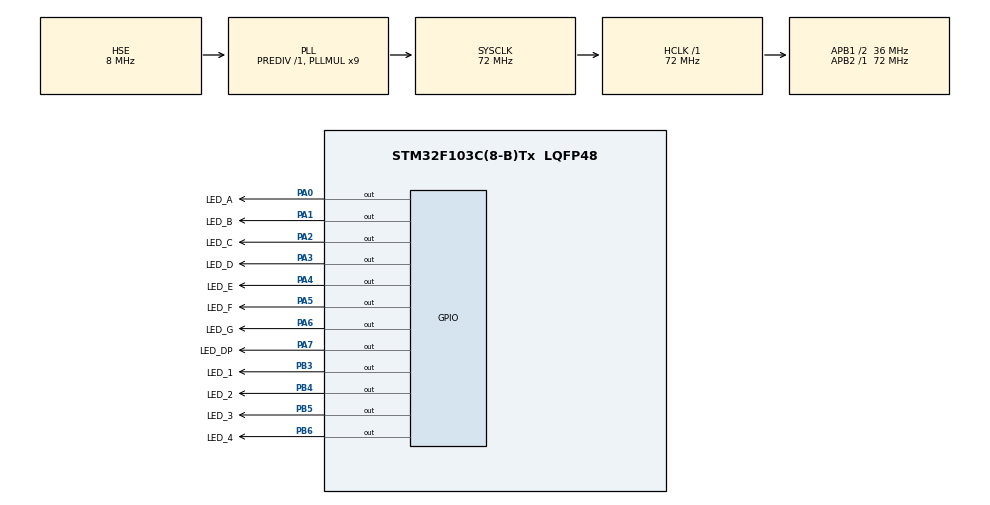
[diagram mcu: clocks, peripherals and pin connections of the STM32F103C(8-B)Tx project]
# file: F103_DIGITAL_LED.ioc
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Mcu.Family=STM32F1
RCC.PLLSourceVirtual=RCC_PLLSOURCE_HSE
PA2.GPIO_PuPd=GPIO_PULLDOWN
PD1-OSC_OUT.Mode=HSE-External-Oscillator
PB6.GPIO_PuPd=GPIO_PULLUP
PA3.GPIO_PuPd=GPIO_PULLDOWN
PA6.PinState=GPIO_PIN_SET
PA6.GPIO_Label=LED_G
PB6.GPIO_Label=LED_4
PD0-OSC_IN.Signal=RCC_OSC_IN
RCC.APB1CLKDivider=RCC_HCLK_DIV2
PA5.PinState=GPIO_PIN_SET
RCC.SYSCLKSource=RCC_SYSCLKSOURCE_PLLCLK
ProjectManager.StackSize=0x400
PA0-WKUP.GPIO_Label=LED_A
PA0-WKUP.Signal=GPIO_Output
PD1-OSC_OUT.Signal=RCC_OSC_OUT
PA13.Signal=SYS_JTMS-SWDIO
PA4.PinState=GPIO_PIN_SET
PA7.PinState=GPIO_PIN_SET
ProjectManager.TargetToolchain=STM32CubeIDE
RCC.HCLKFreq_Value=72000000
RCC.APB2TimFreq_Value=72000000
TIM3.Period=100-1
PB6.Signal=GPIO_Output
PB4.GPIO_PuPd=GPIO_PULLUP
RCC.USBFreq_Value=72000000
PA1.GPIO_PuPd=GPIO_PULLDOWN
PA1.Signal=GPIO_Output
PA7.GPIO_PuPd=GPIO_PULLDOWN
RCC.AHBFreq_Value=72000000
PD0-OSC_IN.Mode=HSE-External-Oscillator
PA5.Signal=GPIO_Output
PA4.GPIO_PuPd=GPIO_PULLDOWN
board=custom
RCC.PLLMUL=RCC_PLL_MUL9
PA0-WKUP.PinState=GPIO_PIN_SET
NVIC.TIM3_IRQn=true\:2\:0\:true\:false\:true\:true\:true
PA2.PinState=GPIO_PIN_SET
RCC.APB2Freq_Value=72000000
PA6.GPIO_PuPd=GPIO_PULLDOWN
PB3.GPIO_PuPd=GPIO_PULLUP
PB4.GPIO_Label=LED_2
PA14.Mode=Serial_Wire
TIM3.Prescaler=72-1
PA5.GPIO_PuPd=GPIO_PULLDOWN
PA1.GPIO_Label=LED_B
PA13.Mode=Serial_Wire
Mcu.Name=STM32F103C(8-B)Tx
PA2.Signal=GPIO_Output
PB3.Signal=GPIO_Output
PA4.Signal=GPIO_Output
RCC.SYSCLKFreq_VALUE=72000000
Mcu.Package=LQFP48
PB5.Signal=GPIO_Output
PA6.Signal=GPIO_Output
PA7.GPIO_Label=LED_DP
PA5.GPIO_Label=LED_F
PB5.GPIO_PuPd=GPIO_PULLUP
PA2.GPIO_Label=LED_C
PA14.Signal=SYS_JTCK-SWCLK
ProjectManager.HeapSize=0x200
PA1.PinState=GPIO_PIN_SET
NVIC.PriorityGroup=NVIC_PRIORITYGROUP_4
PB5.GPIO_Label=LED_3
RCC.APB1TimFreq_Value=72000000
PA3.PinState=GPIO_PIN_SET
PA0-WKUP.GPIO_PuPd=GPIO_PULLDOWN
RCC.APB1Freq_Value=36000000
PB4.PinState=GPIO_PIN_RESET
PA4.GPIO_Label=LED_E
VP_TIM3_VS_ClockSourceINT.Mode=Internal
PB4.Signal=GPIO_Output
PA3.GPIO_Label=LED_D
PA3.Signal=GPIO_Output
PA7.Signal=GPIO_Output
PB3.GPIO_Label=LED_1

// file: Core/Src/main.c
/* USER CODE BEGIN Header */
/**
  ******************************************************************************
  * @file           : main.c
  * @brief          : Main program body
  ******************************************************************************
  * @attention
  *
  * <h2><center>&copy; Copyright (c) 2021 STMicroelectronics.
  * All rights reserved.</center></h2>
  *
  * This software component is licensed by ST under BSD 3-Clause license,
  * the "License"; You may not use this file except in compliance with the
  * License. You may obtain a copy of the License at:
  *                        opensource.org/licenses/BSD-3-Clause
  *
  ******************************************************************************
  */
/* USER CODE END Header */
#include "main.h"
#include "tim.h"
#include "gpio.h"

void SystemClock_Config(void);

int main(void)
{

  /* MCU Configuration--------------------------------------------------------*/

  /* Reset of all peripherals, Initializes the Flash interface and the Systick. */
  HAL_Init();

  /* Configure the system clock */
  SystemClock_Config();

  /* Initialize all configured peripherals */
  MX_GPIO_Init();
  MX_TIM3_Init();
  /* USER CODE BEGIN 2 */
  TIM3_IT_Start();
  /* USER CODE END 2 */

  /* Infinite loop */
  while (1)
  {

    /* USER CODE BEGIN 3 */

//	  Update_LED_BUF(1, 0);Update_LED_BUF(2, 1);Update_LED_BUF(3, 2);Update_LED_BUF(4, 3);
//	  HAL_Delay(1000);
//	  Update_LED_BUF(5, 0);Update_LED_BUF(6, 1);Update_LED_BUF(7, 2);Update_LED_BUF(8, 3);
//	  HAL_Delay(1000);
//	  Update_LED_BUF(9, 0);Update_LED_BUF(0, 1);Update_LED_BUF(0, 2);Update_LED_BUF(0, 3);
//	  HAL_Delay(1000);

	  uint8_t i = 0, pos = 0, pin, pin2;
	  for(pos=0; pos<4; pos++){
	    pin = 0x20;
	    for(i=0; i<5; i++){
	  	  pin |= (0x20>>i);
	  	  pin2 = ~pin;
	  	  Update_LED_BUF(pin2, pos);
	  	  HAL_Delay(100);
	    }
	  }
	  Update_LED_BUF(0xFF, 0); Update_LED_BUF(0xFF, 1); Update_LED_BUF(0xFF, 2); Update_LED_BUF(0xFF, 3);
  }
  /* USER CODE END 3 */
}

void SystemClock_Config(void)
{
  RCC_OscInitTypeDef RCC_OscInitStruct = {0};
  RCC_ClkInitTypeDef RCC_ClkInitStruct = {0};

  /** Initializes the RCC Oscillators according to the specified parameters
  * in the RCC_OscInitTypeDef structure.
  */
  RCC_OscInitStruct.OscillatorType = RCC_OSCILLATORTYPE_HSE;
  RCC_OscInitStruct.HSEState = RCC_HSE_ON;
  RCC_OscInitStruct.HSEPredivValue = RCC_HSE_PREDIV_DIV1;
  RCC_OscInitStruct.HSIState = RCC_HSI_ON;
  RCC_OscInitStruct.PLL.PLLState = RCC_PLL_ON;
  RCC_OscInitStruct.PLL.PLLSource = RCC_PLLSOURCE_HSE;
  RCC_OscInitStruct.PLL.PLLMUL = RCC_PLL_MUL9;
  if (HAL_RCC_OscConfig(&RCC_OscInitStruct) != HAL_OK)
  {
    Error_Handler();
  }
  /** Initializes the CPU, AHB and APB buses clocks
  */
  RCC_ClkInitStruct.ClockType = RCC_CLOCKTYPE_HCLK|RCC_CLOCKTYPE_SYSCLK
                              |RCC_CLOCKTYPE_PCLK1|RCC_CLOCKTYPE_PCLK2;
  RCC_ClkInitStruct.SYSCLKSource = RCC_SYSCLKSOURCE_PLLCLK;
  RCC_ClkInitStruct.AHBCLKDivider = RCC_SYSCLK_DIV1;
  RCC_ClkInitStruct.APB1CLKDivider = RCC_HCLK_DIV2;
  RCC_ClkInitStruct.APB2CLKDivider = RCC_HCLK_DIV1;

  if (HAL_RCC_ClockConfig(&RCC_ClkInitStruct, FLASH_LATENCY_2) != HAL_OK)
  {
    Error_Handler();
  }
}

void Error_Handler(void)
{
  __disable_irq();
  while (1)
  {
  }
}

/************************ (C) COPYRIGHT STMicroelectronics *****END OF FILE****/
